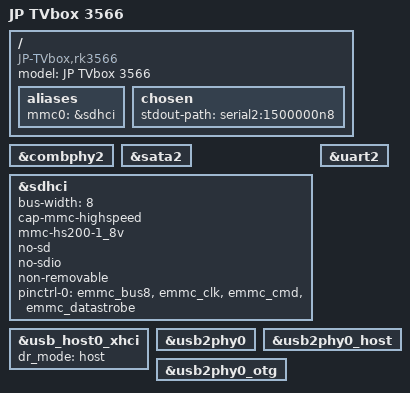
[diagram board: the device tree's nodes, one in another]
// SPDX-License-Identifier: (GPL-2.0+ OR MIT)
/*
 * Minimal U-Boot device tree derived from the JP-TVbox-3566 kernel DTS.
 */

/dts-v1/;

#include "rk3566.dtsi"

/ {
	model = "JP TVbox 3566";
	compatible = "JP-TVbox,rk3566", "rockchip,rk3566";

	aliases {
		mmc0 = &sdhci;
	};

	chosen {
		stdout-path = "serial2:1500000n8";
	};
};

&combphy2 {
	status = "okay";
};

&sata2 {
	status = "okay";
};

&sdhci {
	bus-width = <8>;
	cap-mmc-highspeed;
	mmc-hs200-1_8v;
	no-sd;
	no-sdio;
	non-removable;
	pinctrl-names = "default";
	pinctrl-0 = <&emmc_bus8 &emmc_clk &emmc_cmd &emmc_datastrobe>;
	status = "okay";
};

&uart2 {
	status = "okay";
};

&usb_host0_xhci {
	dr_mode = "host";
	status = "okay";
};

&usb2phy0 {
	status = "okay";
};

&usb2phy0_host {
	status = "okay";
};

&usb2phy0_otg {
	status = "okay";
};
